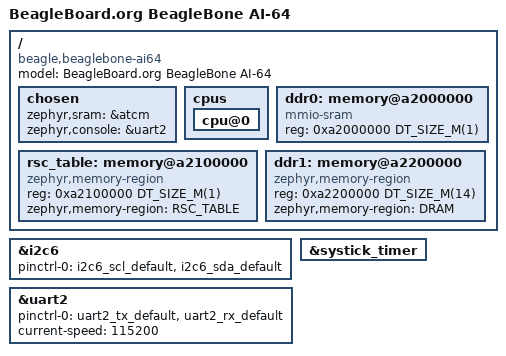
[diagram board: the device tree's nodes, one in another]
/* Copyright (C) 2023 BeagleBoard.org Foundation
 * Copyright (C) 2023 S Prashanth
 * Copyright (c) 2024 Texas Instruments Incorporated
 *	Andrew Davis <afd@ti.com>
 *
 * SPDX-License-Identifier: Apache-2.0
 */

/dts-v1/;

#include <ti/j721e_main_r5.dtsi>
#include "beaglebone_ai64_j721e_main_r5f0_0-pinctrl.dtsi"
#include <freq.h>

/ {
	model = "BeagleBoard.org BeagleBone AI-64";
	compatible = "beagle,beaglebone-ai64";

	chosen {
		zephyr,sram = &atcm;
		zephyr,console = &uart2;
	};

	cpus {
		cpu@0 {
			status = "okay";
		};
	};

	ddr0: memory@a2000000 {
		compatible = "mmio-sram";
		reg = <0xa2000000 DT_SIZE_M(1)>;
	};

	rsc_table: memory@a2100000 {
		compatible = "zephyr,memory-region", "mmio-sram";
		reg = <0xa2100000 DT_SIZE_M(1)>;
		zephyr,memory-region = "RSC_TABLE";
	};

	ddr1: memory@a2200000 {
		compatible = "zephyr,memory-region", "mmio-sram";
		reg = <0xa2200000 DT_SIZE_M(14)>;
		zephyr,memory-region = "DRAM";
	};
};

&i2c6 {
	status = "okay";
	pinctrl-0 = <&i2c6_scl_default &i2c6_sda_default>;
	pinctrl-names = "default";
};

&uart2 {
	status = "okay";
	pinctrl-0 = <&uart2_tx_default &uart2_rx_default>;
	pinctrl-names = "default";
	current-speed = <115200>;
};

&systick_timer {
	status = "okay";
};
